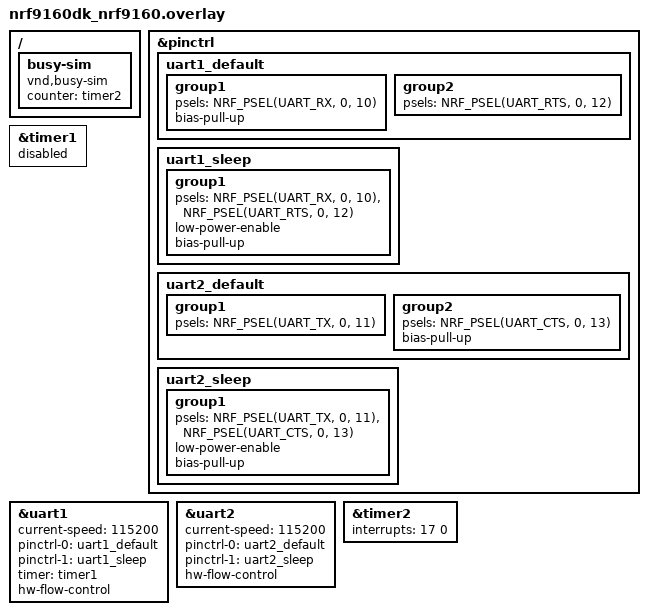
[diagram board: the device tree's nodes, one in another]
/*
 * Copyright (c) 2025 Nordic Semiconductor ASA
 *
 * SPDX-License-Identifier: Apache-2.0
 */

&pinctrl {
	uart1_default: uart1_default {
		group1 {
			psels = <NRF_PSEL(UART_RX, 0, 10)>;
			bias-pull-up;
		};

		group2 {
			psels = <NRF_PSEL(UART_RTS, 0, 12)>;
		};
	};

	uart1_sleep: uart1_sleep {
		group1 {
			psels = <NRF_PSEL(UART_RX, 0, 10)>,
				<NRF_PSEL(UART_RTS, 0, 12)>;
			low-power-enable;
			bias-pull-up;
		};
	};

	uart2_default: uart2_default {
		group1 {
			psels = <NRF_PSEL(UART_TX, 0, 11)>;
		};

		group2 {
			psels = <NRF_PSEL(UART_CTS, 0, 13)>;
			bias-pull-up;
		};
	};

	uart2_sleep: uart2_sleep {
		group1 {
			psels = <NRF_PSEL(UART_TX, 0, 11)>,
				<NRF_PSEL(UART_CTS, 0, 13)>;
			low-power-enable;
			bias-pull-up;
		};
	};
};

&timer1 {
	status = "reserved";
};

dut: &uart1 {
	current-speed = <115200>;
	pinctrl-0 = <&uart1_default>;
	pinctrl-1 = <&uart1_sleep>;
	pinctrl-names = "default", "sleep";
	timer = <&timer1>;
	hw-flow-control;
	status = "okay";
};

dut_aux: &uart2 {
	current-speed = <115200>;
	pinctrl-0 = <&uart2_default>;
	pinctrl-1 = <&uart2_sleep>;
	pinctrl-names = "default", "sleep";
	hw-flow-control;
	status = "okay";
};

&timer2 {
	interrupts = <17 0>;
	status = "okay";
};

/ {
	busy-sim {
		compatible = "vnd,busy-sim";
		counter = <&timer2>;
		status = "okay";
	};
};
